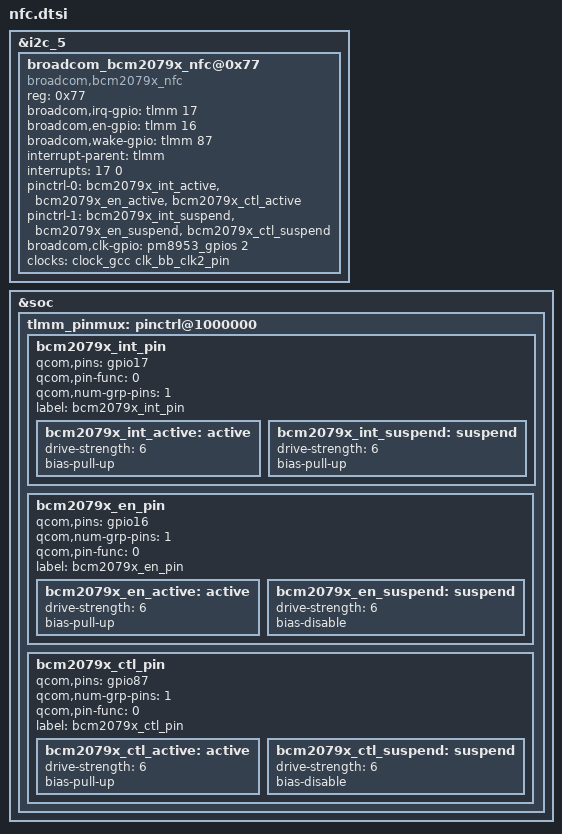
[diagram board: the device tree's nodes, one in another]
/*
 * nubia overwrite dts
 */
&i2c_5 {
	/delete-node/ nq@28;
	/* add for brcm NFC */
        broadcom_bcm2079x_nfc@0x77{
                compatible = "broadcom,bcm2079x_nfc";
                reg = <0x77>;
                broadcom,irq-gpio = <&tlmm 17 0x00>;
                broadcom,en-gpio = <&tlmm 16 0x00>;
                broadcom,wake-gpio = <&tlmm 87 0x00>;
                interrupt-parent = <&tlmm>;
			interrupts = <17 0>;
                interrupt-names = "BRCM_NFC_INT";
                pinctrl-names = "bcm2079x_pin_active","bcm2079x_pin_suspend";
                pinctrl-0 = <&bcm2079x_int_active &bcm2079x_en_active &bcm2079x_ctl_active>;
                pinctrl-1 = <&bcm2079x_int_suspend &bcm2079x_en_suspend &bcm2079x_ctl_suspend>;
                broadcom,clk-gpio = <&pm8953_gpios 2 0x00>;
                clocks = <&clock_gcc clk_bb_clk2_pin>;
                clock-names = "ref_clk";
        };
};
&soc {
        tlmm_pinmux: pinctrl@1000000 {
		bcm2079x_int_pin{
                        qcom,pins = "gpio17";
                        qcom,pin-func = <0>;
                        qcom,num-grp-pins = <1>;
                        label = "bcm2079x_int_pin";

                        bcm2079x_int_active: active {
                                drive-strength = <6>;
                                bias-pull-up;
                        };

                        bcm2079x_int_suspend: suspend {
                                drive-strength = <6>;
                                bias-pull-up;
                        };
                };
		bcm2079x_en_pin{
		
                        qcom,pins = "gpio16";
                        qcom,num-grp-pins = <1>;
                        qcom,pin-func = <0>;
                        label = "bcm2079x_en_pin";
                        bcm2079x_en_active: active {
                                drive-strength = <6>;
                                bias-pull-up;
                        };
                        bcm2079x_en_suspend: suspend {
                                drive-strength = <6>;
                                bias-disable;
                        };
                };
                bcm2079x_ctl_pin{
                        qcom,pins =  "gpio87";
                        //pins = "gpio34";
                        qcom,num-grp-pins = <1>;
                        qcom,pin-func = <0>;
                        label = "bcm2079x_ctl_pin";
                        bcm2079x_ctl_active: active {
                                drive-strength = <6>;
                                bias-pull-up;
                        };
                        bcm2079x_ctl_suspend: suspend {
                                drive-strength = <6>;
                                bias-disable;
                        };
                };
	};
};
